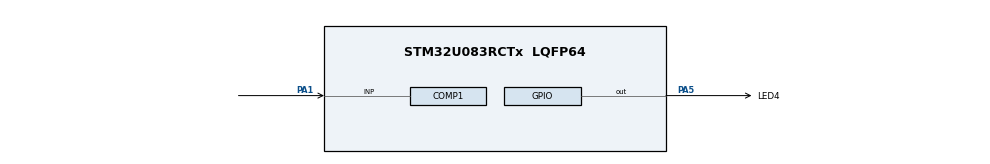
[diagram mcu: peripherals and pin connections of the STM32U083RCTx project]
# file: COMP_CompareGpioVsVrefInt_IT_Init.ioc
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COMP1.Hysteresis=COMP_HYSTERESIS_MEDIUM
COMP1.TriggerMode=COMP_TRIGGERMODE_IT_RISING_FALLING
Mcu.Family=STM32U0
Mcu.Name=STM32U083RCTx
Mcu.Package=LQFP64
NVIC.ADC_COMP1_2_IRQn=true\:0\:0\:false\:false\:false\:false\:true\:true
NVIC.PriorityGroup=NVIC_PRIORITYGROUP_2
PA1.Mode=INP
PA1.Signal=COMP1_INP
PA5.GPIO_Label=LED4
PA5.Signal=GPIO_Output
ProjectManager.HeapSize=0x200
ProjectManager.StackSize=0x400
ProjectManager.TargetToolchain=EWARM V9.20
RCC.ADCFreq_Value=48000000
RCC.AHBFreq_Value=48000000
RCC.CortexFreq_Value=48000000
RCC.HCLKFreq_Value=48000000
RCC.HSE_VALUE=4000000
RCC.HSI48_VALUE=48000000
RCC.HSI_VALUE=16000000
RCC.LSE_VALUE=32768
RCC.MSIClockRangeVal=RCC_MSIRANGE_11
RCC.MSI_VALUE=48000000
RCC.SYSCLKFreq_VALUE=48000000
RCC.SYSCLKSource=RCC_SYSCLKSOURCE_MSI
RCC.USBFreq_Value=48000000
RCC.VCOOutputFreq_Value=64000000
VP_COMP1_VS_VREFINT.Mode=VREFINT
VP_PWR_VS_SECSignals.Mode=Security/Privilege
board=custom

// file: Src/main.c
/* USER CODE BEGIN Header */
/**
  ******************************************************************************
  * @file    Examples_LL/COMP/COMP_CompareGpioVsVrefInt_IT_Init/Src/main.c
  * @author  MCD Application Team
  * @brief   How to use a comparator peripheral to compare a voltage level
  *          on a GPIO pin versus the internal voltage reference (VrefInt),
  *          in interrupt mode.
  *          This example is based on the STM32U0xx COMP LL API;
  *          Peripheral initialization done using LL unitary services functions.
  ******************************************************************************
  * @attention
  *
  * Copyright (c) 2023 STMicroelectronics.
  * All rights reserved.
  *
  * This software is licensed under terms that can be found in the LICENSE file
  * in the root directory of this software component.
  * If no LICENSE file comes with this software, it is provided AS-IS.
  *
  ******************************************************************************
  */
/* USER CODE END Header */
#include "main.h"

void SystemClock_Config(void);
static void MX_GPIO_Init(void);
static void MX_COMP1_Init(void);
/* USER CODE BEGIN PFP */

void Activate_COMP(void);
void LED_On(void);
void LED_Off(void);
void LED_Toggle(void);

/* USER CODE END PFP */

int main(void)
{

  /* MCU Configuration--------------------------------------------------------*/

  /* Reset of all peripherals, Initializes the Flash interface and the Systick. */
  LL_APB1_GRP1_EnableClock(LL_APB1_GRP1_PERIPH_PWR);
  LL_APB1_GRP2_EnableClock(LL_APB1_GRP2_PERIPH_SYSCFG);

  /* System interrupt init*/
  NVIC_SetPriorityGrouping(NVIC_PRIORITYGROUP_2);

  /* SysTick_IRQn interrupt configuration */
  NVIC_SetPriority(SysTick_IRQn, NVIC_EncodePriority(NVIC_GetPriorityGrouping(),3, 0));

  /* Configure the system clock */
  SystemClock_Config();

  /* Initialize all configured peripherals */
  MX_GPIO_Init();
  MX_COMP1_Init();
  /* USER CODE BEGIN 2 */

  /* Activate comparator */
  Activate_COMP();

  /* USER CODE END 2 */

  /* Infinite loop */
  /* USER CODE BEGIN WHILE */
  while (1)
  {
    /* Note: LED state indicates comparator output state and is set into      */
    /*       comparator IRQ handler, refer to function                        */
    /*       "ComparatorTrigger_Callback()".                                  */
         ComparatorTrigger_Callback();
    /* USER CODE END WHILE */

  }
}

void SystemClock_Config(void)
{
  LL_FLASH_SetLatency(LL_FLASH_LATENCY_1);
  while(LL_FLASH_GetLatency() != LL_FLASH_LATENCY_1)
  {
  }

  LL_PWR_SetRegulVoltageScaling(LL_PWR_REGU_VOLTAGE_SCALE1);
  while (LL_PWR_IsActiveFlag_VOS() != 0)
  {
  }
  LL_RCC_MSI_Enable();

   /* Wait till MSI is ready */
  while(LL_RCC_MSI_IsReady() != 1)
  {
  }

  LL_RCC_MSI_EnableRangeSelection();
  LL_RCC_MSI_SetRange(LL_RCC_MSIRANGE_11);
  LL_RCC_SetSysClkSource(LL_RCC_SYS_CLKSOURCE_MSI);

   /* Wait till System clock is ready */
  while(LL_RCC_GetSysClkSource() != LL_RCC_SYS_CLKSOURCE_STATUS_MSI)
  {
  }

  LL_RCC_SetAHBPrescaler(LL_RCC_SYSCLK_DIV_1);
  LL_RCC_SetAPB1Prescaler(LL_RCC_APB1_DIV_1);

  LL_Init1msTick(48000000);

  LL_SetSystemCoreClock(48000000);
}

static void MX_COMP1_Init(void)
{

  LL_COMP_InitTypeDef COMP_InitStruct = {0};

  LL_GPIO_InitTypeDef GPIO_InitStruct = {0};

  /* Peripheral clock enable */
  LL_APB1_GRP2_EnableClock(LL_APB1_GRP2_PERIPH_COMP);

  LL_IOP_GRP1_EnableClock(LL_IOP_GRP1_PERIPH_GPIOA);
  /**COMP1 GPIO Configuration
  PA1   ------> COMP1_INP
  */
  GPIO_InitStruct.Pin = LL_GPIO_PIN_1;
  GPIO_InitStruct.Mode = LL_GPIO_MODE_ANALOG;
  GPIO_InitStruct.Pull = LL_GPIO_PULL_NO;
  LL_GPIO_Init(GPIOA, &GPIO_InitStruct);

  /* COMP1 interrupt Init */
  NVIC_SetPriority(ADC_COMP1_2_IRQn, NVIC_EncodePriority(NVIC_GetPriorityGrouping(),0, 0));
  NVIC_EnableIRQ(ADC_COMP1_2_IRQn);

  COMP_InitStruct.InputPlus = LL_COMP_INPUT_PLUS_IO3;
  COMP_InitStruct.InputMinus = LL_COMP_INPUT_MINUS_VREFINT;
  COMP_InitStruct.InputHysteresis = LL_COMP_HYSTERESIS_MEDIUM;
  COMP_InitStruct.OutputPolarity = LL_COMP_OUTPUTPOL_NONINVERTED;
  COMP_InitStruct.OutputBlankingSource = LL_COMP_BLANKINGSRC_NONE;
  LL_COMP_Init(COMP1, &COMP_InitStruct);
  LL_COMP_SetPowerMode(COMP1, LL_COMP_POWERMODE_HIGHSPEED);

  /* Wait loop initialization and execution */
  /* Note: Variable divided by 2 to compensate partially CPU processing cycles */
  __IO uint32_t wait_loop_index = 0;
  wait_loop_index = (LL_COMP_DELAY_VOLTAGE_SCALER_STAB_US * (SystemCoreClock / (1000000 * 2)));
  while(wait_loop_index != 0)
  {
    wait_loop_index--;
  }
  LL_COMP_SetCommonWindowMode(__LL_COMP_COMMON_INSTANCE(COMP1), LL_COMP_WINDOWMODE_DISABLE);
  LL_COMP_SetCommonWindowOutput(__LL_COMP_COMMON_INSTANCE(COMP1), LL_COMP_WINDOWOUTPUT_EACH_COMP);
  LL_EXTI_ClearFallingFlag_0_31(LL_EXTI_LINE_17);
  LL_EXTI_ClearRisingFlag_0_31(LL_EXTI_LINE_17);
  LL_EXTI_EnableFallingTrig_0_31(LL_EXTI_LINE_17);
  LL_EXTI_EnableRisingTrig_0_31(LL_EXTI_LINE_17);
  LL_EXTI_DisableEvent_0_31(LL_EXTI_LINE_17);
  LL_EXTI_EnableIT_0_31(LL_EXTI_LINE_17);

}

static void MX_GPIO_Init(void)
{
  LL_GPIO_InitTypeDef GPIO_InitStruct = {0};

  /* GPIO Ports Clock Enable */
  LL_IOP_GRP1_EnableClock(LL_IOP_GRP1_PERIPH_GPIOA);

  /**/
  LL_GPIO_ResetOutputPin(LED4_GPIO_Port, LED4_Pin);

  /**/
  GPIO_InitStruct.Pin = LED4_Pin;
  GPIO_InitStruct.Mode = LL_GPIO_MODE_OUTPUT;
  GPIO_InitStruct.Speed = LL_GPIO_SPEED_FREQ_LOW;
  GPIO_InitStruct.OutputType = LL_GPIO_OUTPUT_PUSHPULL;
  GPIO_InitStruct.Pull = LL_GPIO_PULL_NO;
  LL_GPIO_Init(LED4_GPIO_Port, &GPIO_InitStruct);

}

/* USER CODE BEGIN 4 */

/**
  * @brief  Perform comparator activation procedure
  *         (COMP instance: COMP1).
  * @param  None
  * @retval None
  */
void Activate_COMP(void)
{
  __IO uint32_t wait_loop_index = 0;

  /* Enable comparator */
  LL_COMP_Enable(COMP1);

  /* Delay for comparator startup time.                                       */
  /* Compute number of CPU cycles to wait for, from delay in us.              */
  /* Note: Variable divided by 2 to compensate partially                      */
  /*       CPU processing cycles (depends on compilation optimization).       */
  /* Note: If system clock frequency is below 200kHz, wait time will          */
  /*       correspond to the few CPU processing cycles to process this        */
  /*       calculation.                                                       */
  wait_loop_index = ((LL_COMP_DELAY_STARTUP_US * (SystemCoreClock / (100000 * 2))) / 10);
  while(wait_loop_index != 0)
  {
    wait_loop_index--;
  }
}

/**
  * @brief  Turn-on LED4.
  * @param  None
  * @retval None
  */
void LED_On(void)
{
  /* Turn LED on */
  LL_GPIO_SetOutputPin(LED4_GPIO_Port, LED4_Pin);
}

/**
  * @brief  Turn-off LED4.
  * @param  None
  * @retval None
  */
void LED_Off(void)
{
  /* Turn LED off */
  LL_GPIO_ResetOutputPin(LED4_GPIO_Port, LED4_Pin);
}

/**
  * @brief  Toggle LED4.
  * @param  None
  * @retval None
  */
void LED_Toggle(void)
{
  /* Turn LED off */
  LL_GPIO_TogglePin(LED4_GPIO_Port, LED4_Pin);
}

/******************************************************************************/
/*   USER IRQ HANDLER TREATMENT                                               */
/******************************************************************************/

/**
  * @brief  Comparator interruption callback
  * @note   This function is called when comparator threshold is triggered.
  * @retval None
  */
void ComparatorTrigger_Callback()
{
  /* Set LED state in function of comparator output level */
  if (LL_COMP_ReadOutputLevel(COMP1) == LL_COMP_OUTPUT_LEVEL_HIGH)
  {
    LED_On();
  }
  else
  {
    LED_Off();
  }
}

/* USER CODE END 4 */

void Error_Handler(void)
{
  /* USER CODE BEGIN Error_Handler_Debug */
  /* User can add his own implementation to report the HAL error return state */

  /* Turn on LED and remain in infinite loop */
  while (1)
  {
    LED_On();
  }
  /* USER CODE END Error_Handler_Debug */
}
